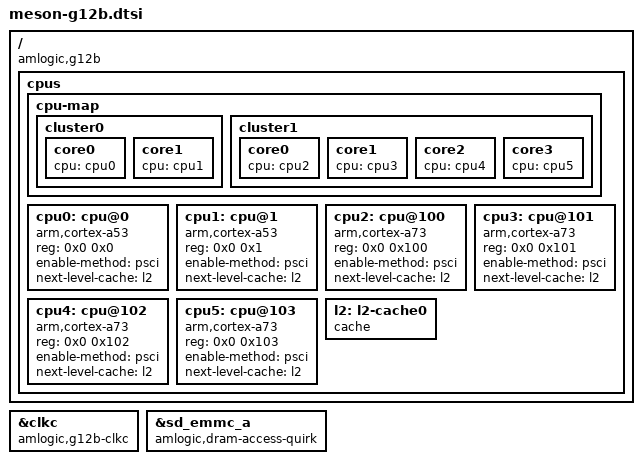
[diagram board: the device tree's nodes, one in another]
// SPDX-License-Identifier: (GPL-2.0+ OR MIT)
/*
 * Copyright (c) 2019 BayLibre, SAS
 * Author: Neil Armstrong <narmstrong@baylibre.com>
 */

#include "meson-g12-common.dtsi"

/ {
	compatible = "amlogic,g12b";

	cpus {
		#address-cells = <0x2>;
		#size-cells = <0x0>;

		cpu-map {
			cluster0 {
				core0 {
					cpu = <&cpu0>;
				};

				core1 {
					cpu = <&cpu1>;
				};
			};

			cluster1 {
				core0 {
					cpu = <&cpu2>;
				};

				core1 {
					cpu = <&cpu3>;
				};

				core2 {
					cpu = <&cpu4>;
				};

				core3 {
					cpu = <&cpu5>;
				};
			};
		};

		cpu0: cpu@0 {
			device_type = "cpu";
			compatible = "arm,cortex-a53";
			reg = <0x0 0x0>;
			enable-method = "psci";
			next-level-cache = <&l2>;
		};

		cpu1: cpu@1 {
			device_type = "cpu";
			compatible = "arm,cortex-a53";
			reg = <0x0 0x1>;
			enable-method = "psci";
			next-level-cache = <&l2>;
		};

		cpu2: cpu@100 {
			device_type = "cpu";
			compatible = "arm,cortex-a73";
			reg = <0x0 0x100>;
			enable-method = "psci";
			next-level-cache = <&l2>;
		};

		cpu3: cpu@101 {
			device_type = "cpu";
			compatible = "arm,cortex-a73";
			reg = <0x0 0x101>;
			enable-method = "psci";
			next-level-cache = <&l2>;
		};

		cpu4: cpu@102 {
			device_type = "cpu";
			compatible = "arm,cortex-a73";
			reg = <0x0 0x102>;
			enable-method = "psci";
			next-level-cache = <&l2>;
		};

		cpu5: cpu@103 {
			device_type = "cpu";
			compatible = "arm,cortex-a73";
			reg = <0x0 0x103>;
			enable-method = "psci";
			next-level-cache = <&l2>;
		};

		l2: l2-cache0 {
			compatible = "cache";
		};
	};
};

&clkc {
	compatible = "amlogic,g12b-clkc";
};

&sd_emmc_a {
	amlogic,dram-access-quirk;
};
